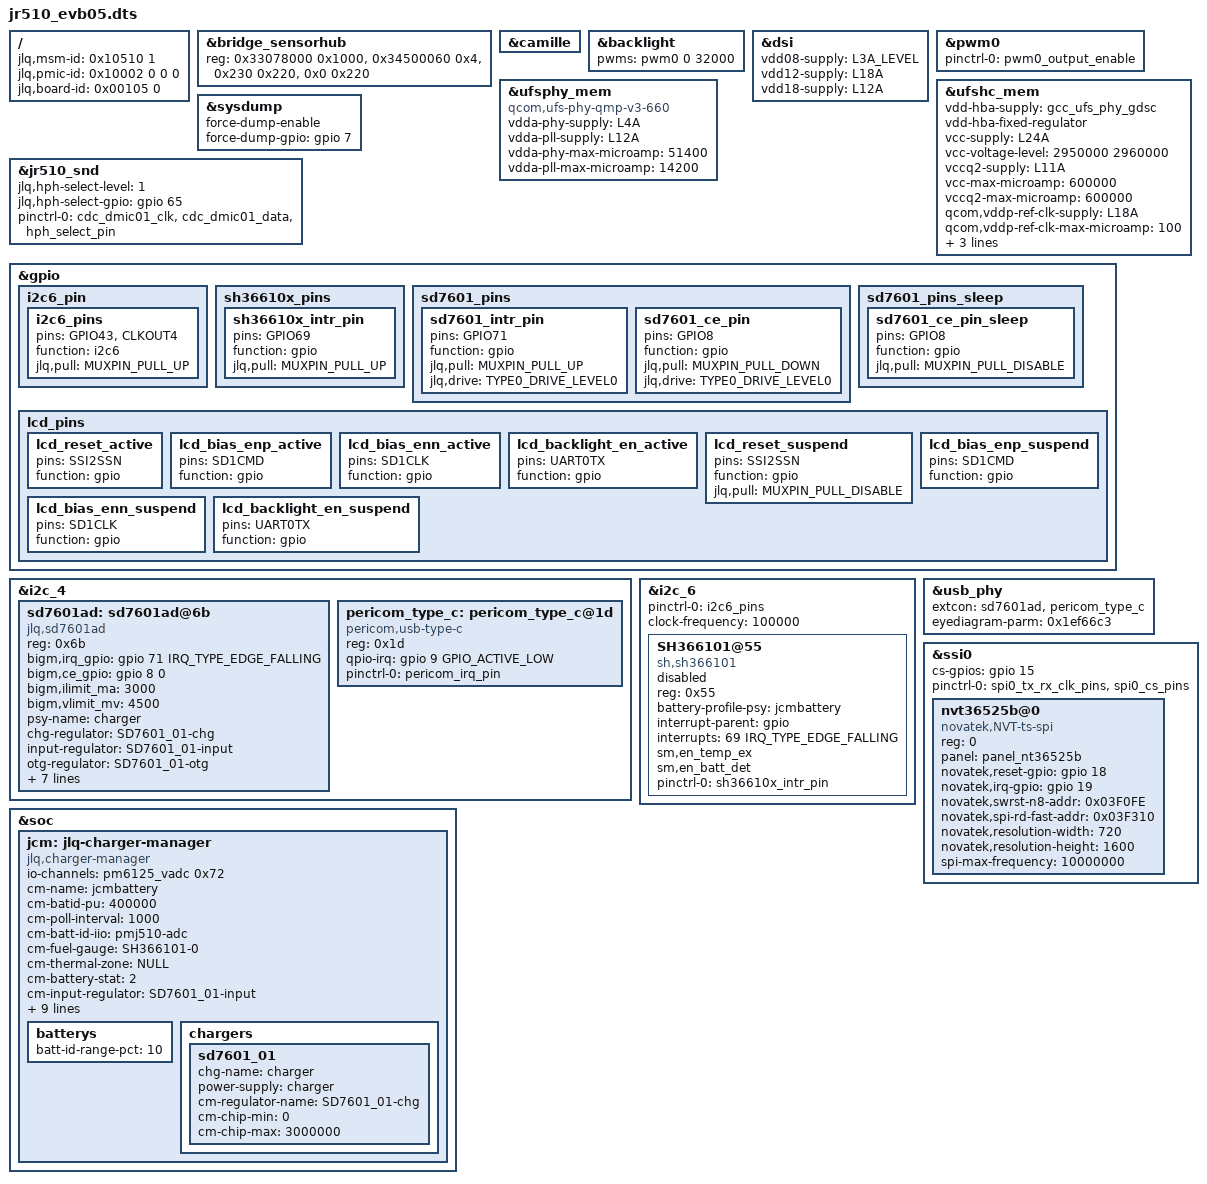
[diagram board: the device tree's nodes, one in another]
// SPDX-License-Identifier: GPL-2.0+
/dts-v1/;
/plugin/;

#include <dt-bindings/interrupt-controller/arm-gic.h>
#include <dt-bindings/jlq/jr510/irqs.h>
#include <dt-bindings/gpio/gpio.h>

#include "jr510_camera_sensor_evb05.dtsi"
#include "jr510_pinctrl_evb.dtsi"
#include "aw87xxx.dtsi"
#include "pm6125_adc_tz_evb.dtsi"

/ {
	jlq,msm-id     = <0x10510 1>;
	jlq,pmic-id    = <0x10002 0 0 0>;
	jlq,board-id   = <0x00105 0>;
};

&bridge_sensorhub {
	reg = <0x33078000 0x1000>, <0x34500060 0x4>, <0x230 0x220>, <0x0 0x220>;
	status = "okay";
};

&camille {
	status = "okay";
};

&backlight {
	pwms = <&pwm0 0 32000>;
};

#include "dsi_panel_nt36525b_evb05.dtsi"

&dsi {
	vdd08-supply = <&L3A_LEVEL>;
	vdd12-supply = <&L18A>;
	vdd18-supply = <&L12A>;
};

&pwm0 {
	pinctrl-names = "default";
	pinctrl-0 = <&pwm0_output_enable>;
};

&ufsphy_mem {
	compatible = "qcom,ufs-phy-qmp-v3-660";

	vdda-phy-supply = <&L4A>; /* 0.9v */
	vdda-pll-supply = <&L12A>; /* 1.8v */
	vdda-phy-max-microamp = <51400>;
	vdda-pll-max-microamp = <14200>;

	status = "okay";
};

&ufshc_mem {
	vdd-hba-supply = <&gcc_ufs_phy_gdsc>;
	vdd-hba-fixed-regulator;
	vcc-supply = <&L24A>;
	vcc-voltage-level = <2950000 2960000>;
	vccq2-supply = <&L11A>;
	vcc-max-microamp = <600000>;
	vccq2-max-microamp = <600000>;

	qcom,vddp-ref-clk-supply = <&L18A>;
	qcom,vddp-ref-clk-max-microamp = <100>;
	qcom,vddp-ref-clk-min-uV = <1232000>;
	qcom,vddp-ref-clk-max-uV = <1232000>;

	qcom,disable-lpm;
};

#include "wl2866d-regulator.dtsi"


&sysdump {
	force-dump-enable;
	force-dump-gpio = <&gpio 7 GPIO_ACTIVE_HIGH>;
};

&jr510_snd {
	jlq,hph-select-level = <1>;
	jlq,hph-select-gpio = <&gpio 65 GPIO_ACTIVE_HIGH>;

	pinctrl-names = "default";
	pinctrl-0 = <&cdc_dmic01_clk &cdc_dmic01_data &hph_select_pin>;
};

&gpio{
	i2c6_pin {
		i2c6_pins:i2c6_pins {
			pins = "GPIO43", "CLKOUT4";
			function = "i2c6";
			jlq,pull = <MUXPIN_PULL_UP>;
		};
	};
	sh36610x_pins:sh36610x_pins {
		sh36610x_intr_pin:sh36610x_intr_pin {
			pins = "GPIO69";
			function = "gpio";
			jlq,pull = <MUXPIN_PULL_UP>;
		};
	};
	sd7601_pins:sd7601_pins {
		sd7601_intr_pin:sd7601_intr_pin {
			pins = "GPIO71";
			function = "gpio";
			jlq,pull = <MUXPIN_PULL_UP>;
			jlq,drive = <TYPE0_DRIVE_LEVEL0>;
		};
		sd7601_ce_pin:sd7601_ce_pin {
			pins = "GPIO8";
			function = "gpio";
			jlq,pull = <MUXPIN_PULL_DOWN>;
			jlq,drive = <TYPE0_DRIVE_LEVEL0>;
		};
	};
	sd7601_pins_sleep:sd7601_pins_sleep {
		sd7601_ce_pin_sleep {
			pins = "GPIO8";
			function = "gpio";
			jlq,pull = <MUXPIN_PULL_DISABLE>;
		};
	};
	lcd_pins {
		lcd_reset_active:lcd_reset_active {
			pins = "SSI2SSN";
			function = "gpio";
		};

		lcd_bias_enp_active:lcd_bias_enp_active {
			pins = "SD1CMD";
			function = "gpio";
		};

		lcd_bias_enn_active:lcd_bias_enn_active {
			pins = "SD1CLK";
			function = "gpio";
		};

		lcd_backlight_en_active:lcd_backlight_en_active {
			pins = "UART0TX";
			function = "gpio";
		};

		lcd_reset_suspend:lcd_reset_suspend {
			pins = "SSI2SSN";
			function = "gpio";
			jlq,pull = <MUXPIN_PULL_DISABLE>;
		};

		lcd_bias_enp_suspend:lcd_bias_enp_suspend {
			pins = "SD1CMD";
			function = "gpio";
		};

		lcd_bias_enn_suspend:lcd_bias_enn_suspend {
			pins = "SD1CLK";
			function = "gpio";
		};

		lcd_backlight_en_suspend:lcd_backlight_en_suspend {
			pins = "UART0TX";
			function = "gpio";
		};
	};
};
&i2c_4 {
	sd7601ad:sd7601ad@6b {
		reg = <0x6b>;
		compatible = "jlq,sd7601ad";
		bigm,irq_gpio = <&gpio 71 IRQ_TYPE_EDGE_FALLING>;
		bigm,ce_gpio = <&gpio 8 0>;
		bigm,ilimit_ma = <3000>;
		bigm,vlimit_mv = <4500>;
		psy-name = "charger";
		chg-regulator = "SD7601_01-chg";
		input-regulator = "SD7601_01-input";
		otg-regulator = "SD7601_01-otg";
		ch-extcon = "SD7601_01-chg-extcon";
		battery-profile-psy = "jcmbattery";
		interrupt-parent = <&gpio>;
		interrupts = <71 IRQ_TYPE_EDGE_FALLING>;
		pinctrl-names = "default", "sleep";
		pinctrl-0 = <&sd7601_pins>;
		pinctrl-1 = <&sd7601_pins_sleep>;
		phy-supply = <&L15A>;
	};

	pericom_type_c: pericom_type_c@1d {
		compatible = "pericom,usb-type-c";
		reg = <0x1d>;
		qpio-irq = <&gpio 9 GPIO_ACTIVE_LOW>;
		pinctrl-names = "default";
		pinctrl-0 = <&pericom_irq_pin>;
	};
};

&i2c_6 {
	pinctrl-names = "default";
	pinctrl-0 = <&i2c6_pins>;
	clock-frequency = <100000>;
	SH366101@55 {
		reg = <0x55>;
		compatible = "sh,sh366101";
		status = "disabled";
		battery-profile-psy = "jcmbattery";
		interrupt-parent = <&gpio>;
		interrupts = <69 IRQ_TYPE_EDGE_FALLING>;
		sm,en_temp_ex;
		sm,en_batt_det;
		pinctrl-names = "default";
		pinctrl-0 = <&sh36610x_intr_pin>;
		#include "sh366101_fg_data.dtsi"
	};
};

&usb_phy {
	extcon = <&sd7601ad>, <&pericom_type_c>;
	eyediagram-parm = <0x1ef66c3>;
};

&ssi0 {
	status = "okay";
	cs-gpios  = <&gpio 15 0>;
	pinctrl-names = "default";
	pinctrl-0 = <&spi0_tx_rx_clk_pins &spi0_cs_pins>;

	nvt36525b@0 {
		reg = <0>;
		status = "okay";
		panel = <&panel_nt36525b>;
		compatible = "novatek,NVT-ts-spi";
		novatek,reset-gpio = <&gpio 18 0>;
		novatek,irq-gpio = <&gpio 19 0>;
		novatek,swrst-n8-addr = <0x03F0FE>;
		novatek,spi-rd-fast-addr = <0x03F310>;
		novatek,resolution-width = /bits/ 16 <720>;
		novatek,resolution-height = /bits/ 16 <1600>;
		spi-max-frequency = <10000000>;
	};
};

&soc {
	jcm:jlq-charger-manager {
		compatible = "jlq,charger-manager";
		io-channels = <&pm6125_vadc 0x72>;
		io-channel-names = "Bat-ID";
		#io-channel-cells = <1>;
		#cooling-cells = <2>;

		cm-name = "jcmbattery";
		cm-batid-pu = <400000>;
		cm-poll-interval = <1000>;
		cm-batt-id-iio = "pmj510-adc";
		cm-fuel-gauge = "SH366101-0";
		cm-thermal-zone = "NULL";
		cm-battery-stat = <2>;
		cm-input-regulator = "SD7601_01-input";
		cm-steper-intv-ms = <500>;
		cm-steper-current-ma = <400>;
		otg_regulator = "SD7601_01-otg";
		otg-boost-current-ua = <1200000>;
		otg-boost-volt-uv = <5150000>;
		jlq,batteryless-platform;
		extcon = <&sd7601ad>, <&pericom_type_c>;
		jlq,thermal-mitigation = <	3000000  2500000 2200000
									1800000  1600000 1400000 1000000>;
		batterys{
			batt-id-range-pct = <10>;
#include "JLQ_4000mAH_SD7601_SH366101_Jun15th2020_DTSI.dtsi"
#include "JLQ_SUNWODA_5000mAH_SD7601_SH366101_Jun15th2020_DTSI.dtsi"
		};
		chargers{
			sd7601_01{
				chg-name = "charger";
				power-supply = "charger";
				cm-regulator-name = "SD7601_01-chg";
				cm-chip-min = <0>;
				cm-chip-max = <3000000>;
			};
		};
	};
};
